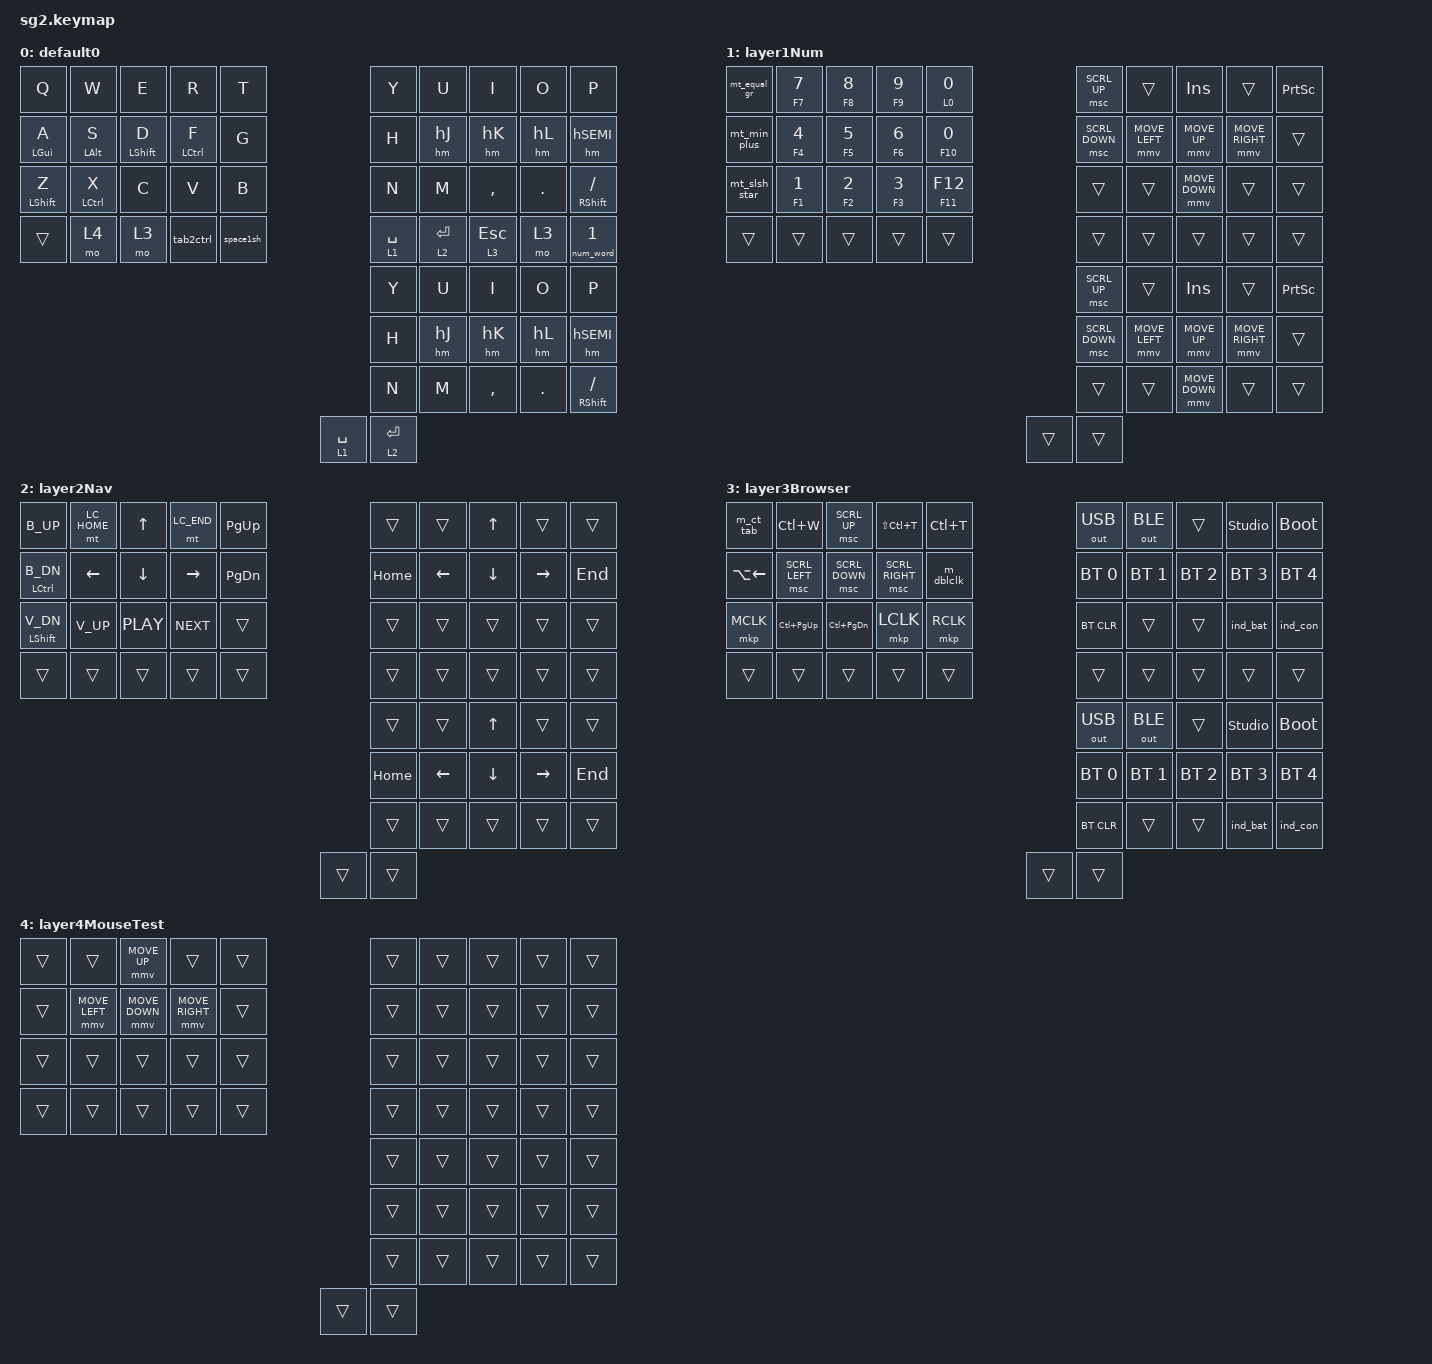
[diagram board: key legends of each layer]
#include <behaviors.dtsi>
#include <behaviors/rgbled_widget.dtsi>
#include <behaviors/num_word.dtsi>
#include <dt-bindings/zmk/keys.h>
#include <dt-bindings/zmk/bt.h>
#include <dt-bindings/zmk/outputs.h>

#define ZMK_POINTING_DEFAULT_SCRL_VAL 50
#include <dt-bindings/zmk/pointing.h>

#define hA    LGUI   A
#define hS    LALT   S
#define hD    LSHIFT D
#define hF    LCTRL  F
#define hJ    RCTRL  J
#define hK    RSHIFT K
#define hL    RALT   L
#define hSEMI RGUI   SEMI


&num_word {
  continue-list = <BSPC DEL DOT COMMA PLUS MINUS STAR FSLH EQUAL SPACE>;
  ignore-modifiers;
};

&msc {
  x-input-code = <INPUT_REL_HWHEEL>;
  y-input-code = <INPUT_REL_WHEEL>;
  time-to-max-speed-ms = <500>;
  acceleration-exponent = <1>;
};

//   888b     d888
//   8888b   d8888
//   88888b.d88888
//   888Y88888P888  8888b.   .d8888b 888d888 .d88b.  .d8888b
//   888 Y888P 888     "88b d88P"    888P"  d88""88b 88K
//   888  Y8P  888 .d888888 888      888    888  888 "Y8888b.
//   888   "   888 888  888 Y88b.    888    Y88..88P      X88
//   888       888 "Y888888  "Y8888P 888     "Y88P"   88888P'
/ {
    macros {
        ZMK_MACRO(task_manager, wait-ms = <30>; tap-ms = <40>; bindings
            = <&macro_press   &kp LCTRL &kp LSHIFT>
            , <&macro_tap     &kp ESC>
            , <&macro_release &kp LSHIFT &kp LCTRL>
            ;
        )

        ZMK_MACRO(m_al_tab, wait-ms = <30>; tap-ms = <40>; bindings
            = <&macro_press   &kp LALT>
            , <&macro_tap     &kp TAB>
            , <&macro_pause_for_release>
            , <&macro_release &kp LALT>
            ;
        )

        ZMK_MACRO(m_ct_tab, wait-ms = <30>; tap-ms = <40>; bindings
            = <&macro_press   &kp LCTRL>
            , <&macro_tap     &kp TAB>
            , <&macro_pause_for_release>
            , <&macro_release &kp LCTRL>
            ;
        )

        #define short_m wait-ms = <20>; tap-ms = <20>; bindings =

        ZMK_MACRO(m_copy_all,   short_m <&macro_tap &kp LC(HOME) &kp LC(LS(END)) &kp LC(INS) &kp LC(C)                        > ; )
        ZMK_MACRO(m_paste_all,  short_m <&macro_tap &kp LC(HOME) &kp LC(LS(END)) &kp LS(INS)                                  > ; )
        ZMK_MACRO(m_cut_all,    short_m <&macro_tap &kp LC(HOME) &kp LC(LS(END)) &kp LS(DEL)                                  > ; )
        ZMK_MACRO(m_copy,       short_m <&macro_tap &kp LC(INS) &kp LC(C)                                                     > ; )
        ZMK_MACRO(m_paste,      short_m <&macro_tap &kp LS(INS)                                                               > ; )
        ZMK_MACRO(m_cut,        short_m <&macro_tap &kp LS(DEL)                                                               > ; )
        ZMK_MACRO(m_backsp,     short_m <&macro_tap &kp BSPC                                                                  > ; )
        ZMK_MACRO(m_del_line,   short_m <&macro_tap &kp HOME &kp HOME &kp LS(END) &kp LS(RIGHT) &kp DEL                       > ; )
        ZMK_MACRO(m_undo,       short_m <&macro_tap &kp LC(Z)                                                                 > ; )
        ZMK_MACRO(m_redo,       short_m <&macro_tap &kp LC(LS(Z))                                                             > ; )
        ZMK_MACRO(m_go_back,    short_m <&macro_tap &kp LA(LEFT)                                                              > ; )
        ZMK_MACRO(m_close_tab,  short_m <&macro_tap &kp LC(W)                                                                 > ; )
        ZMK_MACRO(m_new_tab,    short_m <&macro_tap &kp LC(T)                                                                 > ; )
        ZMK_MACRO(m_reopen_tab, short_m <&macro_tap &kp LC(LS(T))                                                             > ; )
        ZMK_MACRO(m_clip_man,   short_m <&macro_tap &kp LG(V)                                                                 > ; )
        ZMK_MACRO(m_clip_prev,  short_m <&macro_tap &kp LG(V)>, <&macro_wait_time 200>, <&macro_tap &kp DOWN &kp DOWN &kp RET > ; )
        ZMK_MACRO(m_search,     short_m <&macro_tap &kp LC(C) &kp LC(F) &kp LC(V)                                             > ; )
        ZMK_MACRO(macro1,       short_m <&macro_tap &kp STAR &kp LS(U) &kp LPAR &kp LS(I) &kp RPAR &kp LS(O) &kp UNDER &kp RET> ; )
        ZMK_MACRO(m_dblclk,     short_m <&macro_tap &mkp LCLK &mkp LCLK                                                       > ; )
        ZMK_MACRO(m_bs,         short_m <&macro_tap &kp CAPS                                                                  > ; )
        ZMK_MACRO(m_bs_caps,    short_m <&macro_tap &kp CAPS &kp LC(BSPC)                                                     > ; )

        ZMK_MACRO(m_dot,          short_m <&macro_press &kp LALT>, <&macro_tap &kp KP_N4 &kp KP_N6>, <&macro_release &kp LALT>; ) // Alt + 46 = .
        ZMK_MACRO(m_com,          short_m <&macro_press &kp LALT>, <&macro_tap &kp KP_N4 &kp KP_N4>, <&macro_release &kp LALT>; ) // Alt + 44 = ,
        ZMK_MACRO(m_slash,        short_m <&macro_press &kp LALT>, <&macro_tap &kp KP_N4 &kp KP_N7>, <&macro_release &kp LALT>; ) // Alt + 47 = /
        ZMK_MACRO(m_backslash,    short_m <&macro_press &kp LALT>, <&macro_tap &kp KP_N9 &kp KP_N2>, <&macro_release &kp LALT>; ) // Alt + 92 = backslash
        ZMK_MACRO(m_colon,        short_m <&macro_press &kp LALT>, <&macro_tap &kp KP_N5 &kp KP_N8>, <&macro_release &kp LALT>; ) // Alt + 58 = colon
        ZMK_MACRO(m_semicolon,    short_m <&macro_press &kp LALT>, <&macro_tap &kp KP_N5 &kp KP_N9>, <&macro_release &kp LALT>; ) // Alt + 59 = semicolon
        ZMK_MACRO(m_semicolon_end,short_m <&macro_tap &kp END &m_semicolon>; )
        ZMK_MACRO(m_lpar,         short_m <&macro_press &kp LALT>, <&macro_tap &kp KP_N4 &kp KP_N0>, <&macro_release &kp LALT>; ) // Alt + 40 = (
        ZMK_MACRO(m_lbkt,         short_m <&macro_press &kp LALT>, <&macro_tap &kp KP_N9 &kp KP_N1>, <&macro_release &kp LALT>; ) // Alt + 91 = [
        ZMK_MACRO(m_lbrc,         short_m <&macro_press &kp LALT>, <&macro_tap &kp KP_N1 &kp KP_N2 &kp KP_N3>, <&macro_release &kp LALT>; ) // Alt + 123 = {
        ZMK_MACRO(m_lt,           short_m <&macro_press &kp LALT>, <&macro_tap &kp KP_N6 &kp KP_N0>, <&macro_release &kp LALT>; ) // Alt + 60 = <
        ZMK_MACRO(m_quote,        short_m <&macro_press &kp LALT>, <&macro_tap &kp KP_N3 &kp KP_N4>, <&macro_release &kp LALT>; ) // Alt + 34 = "
        ZMK_MACRO(m_apos,         short_m <&macro_press &kp LALT>, <&macro_tap &kp KP_N3 &kp KP_N9>, <&macro_release &kp LALT>; ) // Alt + 39 = '

        layer_mod: layer_mod {
            compatible = "zmk,behavior-macro-two-param";
            wait-ms = <0>;
            tap-ms = <0>;
            #binding-cells = <2>;
            bindings
                = <&macro_param_1to1>
                , <&macro_press &mo MACRO_PLACEHOLDER>
                , <&macro_param_2to1>
                , <&macro_press &kp MACRO_PLACEHOLDER>
                , <&macro_pause_for_release>
                , <&macro_param_2to1>
                , <&macro_release &kp MACRO_PLACEHOLDER>
                , <&macro_param_1to1>
                , <&macro_release &mo MACRO_PLACEHOLDER>
                ;
        };

        m_cs_layer2: layer_mod_ctrl_shift_layer2 {
            compatible = "zmk,behavior-macro";
            wait-ms = <30>;
            tap-ms = <30>;
            #binding-cells = <0>;
            bindings
                = <&macro_press &mo 2 &kp LCTRL &kp LSHFT>
                , <&macro_pause_for_release>
                , <&macro_release &mo 2 &kp LCTRL &kp LSHFT>
                ;
        };
    };


    //   888888b.            888                        d8b
    //   888  "88b           888                        Y8P
    //   888  .88P           888
    //   8888888K.   .d88b.  88888b.   8888b.  888  888 888  .d88b.  888d888 .d8888b
    //   888  "Y88b d8P  Y8b 888 "88b     "88b 888  888 888 d88""88b 888P"   88K
    //   888    888 88888888 888  888 .d888888 Y88  88P 888 888  888 888     "Y8888b.
    //   888   d88P Y8b.     888  888 888  888  Y8bd8P  888 Y88..88P 888          X88
    //   8888888P"   "Y8888  888  888 "Y888888   Y88P   888  "Y88P"  888      88888P'


    behaviors {

        ht: left_positional_hold_tap {  // allows shift with mouse
            compatible = "zmk,behavior-hold-tap";
            #binding-cells = <2>;
            flavor = "tap-unless-interrupted";
            tapping-term-ms = <400>;
            quick-tap-ms = <200>;
            bindings = <&kp>, <&kp>;
        };

        hm: homerow_mods {  // allows repeating z
            compatible = "zmk,behavior-hold-tap";
            #binding-cells = <2>;
            tapping-term-ms = <200>;
            quick-tap-ms = <0>;
            flavor = "tap-preferred";
            bindings = <&kp>, <&kp>;
            // retro-tap;
        };

        #define short_ht compatible = "zmk,behavior-hold-tap"; #binding-cells = <2>; flavor = "tap-preferred"; tapping-term-ms = <200>; quick-tap-ms = <0>;

        //                                                           hold            tap
        ht_dot:           hold_tap_dot           { short_ht bindings = <&m_com>,       <&m_dot>; };
        ht_paren_bracket: hold_tap_paren_bracket { short_ht bindings = <&m_lbkt>,      <&m_lpar>; };
        ht_brace_angle:   hold_tap_brace_angle   { short_ht bindings = <&m_lt>,        <&m_lbrc>; };
        ht_semi_colon:    hold_tap_semi_colon    { short_ht bindings = <&m_colon>,     <&m_semicolon>; };
        ht_quote_apos:    hold_tap_quote_apos    { short_ht bindings = <&m_apos>,      <&m_quote>; };
        // ht_under_minus:   hold_tap_under_minus   { short_ht bindings = <&kp MINUS>, <&kp UNDER>; };
        ht_slash:         hold_tap_slash         { short_ht bindings = <&m_backslash>, <&m_slash>; };
        ht_copy_all:      hold_tap_copy_all      { short_ht bindings = <&m_copy_all>,  <&m_copy>; };
        ht_paste_all:     hold_tap_paste_all     { short_ht bindings = <&m_paste_all>, <&m_paste>; };
        ht_cut_all:       hold_tap_cut_all       { short_ht bindings = <&m_cut_all>,   <&m_cut>; };
        ht_backsp_line:   hold_tap_backsp_line   { short_ht bindings = <&m_del_line>,  <&m_backsp>; };
        ht_clip_man:      hold_tap_clip_man_prev { short_ht bindings = <&m_clip_prev>, <&m_clip_man>; };
        ht_undo_redo:     hold_tap_undo_redo     { short_ht bindings = <&m_redo>,      <&m_undo>; };
        ht_back_clos:     hold_tap_go_back_close { short_ht bindings = <&m_close_tab>, <&m_go_back>; };
        ht_new_reop:      hold_tap_new_reop      { short_ht bindings = <&m_reopen_tab>,<&m_new_tab>; };
        ht_bs_caps:       hold_tap_bs_caps       { short_ht bindings = <&m_bs_caps>,   <&m_bs>; };

        #define mt_under_minus      mt MINUS         UNDER

        space1sh: space_layer1_shift {
            compatible = "zmk,behavior-mod-morph"; #binding-cells = <0>;
            bindings = <&lt 1 SPACE>, <&layer_mod 1 LSHIFT>;
            mods = <(MOD_LSFT)>; keep-mods = <(MOD_LSFT)>;
        };

        tab2ctrl: tab_layer2_ctrl {
            compatible = "zmk,behavior-mod-morph"; #binding-cells = <0>;
            bindings = <&lt 2 TAB>, <&layer_mod 2 LCTRL>;
            mods = <(MOD_LCTL)>; keep-mods = <(MOD_LCTL)>;
        };

        nav_word: nav_word {
            compatible = "zmk,behavior-auto-layer";
            #binding-cells = <1>;
            continue-list = <LEFT DOWN UP RIGHT PG_DN PG_UP HOME END>;
            ignore-modifiers;
        };
    };


    //     .d8888b.                         888
    //    d88P  Y88b                        888
    //    888    888                        888
    //    888         .d88b.  88888b.d88b.  88888b.   .d88b.  .d8888b
    //    888        d88""88b 888 "888 "88b 888 "88b d88""88b 88K
    //    888    888 888  888 888  888  888 888  888 888  888 "Y8888b.
    //    Y88b  d88P Y88..88P 888  888  888 888 d88P Y88..88P      X88
    //     "Y8888P"   "Y88P"  888  888  888 88888P"   "Y88P"   88888P'


    combos {
        compatible = "zmk,combos";
        combo_del      { key-positions = <11 12 13>; bindings = <&kp DEL      >; layers = <0 1>; };  // SDF
        combo_del2     { key-positions = <01 02   >; bindings = <&kp DEL      >; layers = <0 1>; };  // WE
        combo_esc      { key-positions = <11 13   >; bindings = <&kp ESC      >; layers = <0 1 2>; };  // SF
        combo_escR     { key-positions = <16 18   >; bindings = <&kp ESC      >; layers = <0 1 2>; };  // JL
        combo_esc_r    { key-positions = <46 48   >; bindings = <&kp ESC      >; layers = <0 1 2>; };  // JL
        combo_ret      { key-positions = <12 13   >; bindings = <&kp RET      >; layers = <0 1>; };  // DF
        combo_retR     { key-positions = <16 17   >; bindings = <&kp RET      >; layers = <0 1>; };  // JK
        combo_ret_r    { key-positions = <46 47   >; bindings = <&kp RET      >; layers = <0 1>; };  // JK
        combo_rbkt     { key-positions = < 7  8  9>; bindings = <&kp RBKT     >; layers = <0  >; };  // IOP
        combo_lbkt     { key-positions = < 8  9   >; bindings = <&kp LBKT     >; layers = <0  >; };  // OP
        combo_bslh     { key-positions = <28 29   >; bindings = <&kp BSLH     >; layers = <0  >; };  // >?
        combo_apos     { key-positions = <18 19   >; bindings = <&kp APOS     >; layers = <0  >; };  // L:
        combo_rbkt_r   { key-positions = <42 43 44>; bindings = <&kp RBKT     >; layers = <0  >; };  // IOP
        combo_lbkt_r   { key-positions = <43 44   >; bindings = <&kp LBKT     >; layers = <0  >; };  // OP
        combo_bslh_r   { key-positions = <53 54   >; bindings = <&kp BSLH     >; layers = <0  >; };  // >?
        combo_esc2_r   { key-positions = <49 54   >; bindings = <&kp ESC      >; layers = <0  >; };  // ;/
        combo_ret2_r   { key-positions = <44 49   >; bindings = <&kp RET      >; layers = <0  >; };  // p;
        combo_apos_r   { key-positions = <48 49   >; bindings = <&kp APOS     >; layers = <0  >; };  // L:
        combo_task     { key-positions = <00 01   >; bindings = <&task_manager>; layers = <0  >; };  // QW
        combo_cshf     { key-positions = <20 13   >; bindings = <&sk LS(LCTRL)>; layers = <0  >; };  // ZF
        combo_c        { key-positions = <00 13   >; bindings = <&sk LCTRL    >; layers = <0  >; };  // QF
        combo_macro1   { key-positions = < 7 16   >; bindings = <&macro1      >; layers = <0  >; };  // IJ
        combo_macro1_r { key-positions = <42 46   >; bindings = <&macro1      >; layers = <0  >; };  // IJ
        combo_shift1   { key-positions = <12 34   >; bindings = <&layer_mod 1 LSHIFT>; layers = <0>; slow-release;};  // Dspace
        combo_ctrl1    { key-positions = <13 34   >; bindings = <&layer_mod 1 LCTRL >; layers = <0>; slow-release;};  // Fspace
        combo_capsw    { key-positions = <10 20   >; bindings = <&caps_word>;            layers = <0>; };  // AZ
        combo_capsw2   { key-positions = <12 17   >; bindings = <&caps_word>;            layers = <0>; };  // DK
        combo_capsw2_r { key-positions = <12 47   >; bindings = <&caps_word>;            layers = <0>; };  // DK
        combo_brack1   { key-positions = <03 04   >; bindings = <&ht_paren_bracket 0 0>; layers = <0>; };  // RT
    //  00q 01w 02e 03r 04t         05y 06u 07i 08o 09p
    //  10a 11s 12d 13f 14g         15h 16j 17k 18l 19;
    //  20z 21x 22c 23v 24b         25n 26m 27, 28. 29/
    //      30  31  32  33t 34s 35s 36r 37e 38 39
    //                              40y 41u 42i 43o 44p
    //                              45h 46j 47k 48l 49;
    //                              50n 51m 52, 53. 54/
    //                          55s 56r
        combo_brack2   { key-positions = <13 14   >; bindings = <&ht_brace_angle   0 0>; layers = <0>; };  // FG
        combo_caps_bs  { key-positions = <10 13   >; bindings = <&ht_bs_caps       0 0>; layers = <0>; };  // AF
        combo_colon    { key-positions = <03 13   >; bindings = <&ht_semi_colon    0 0>; layers = <0>; };  // RF
        combo_quote    { key-positions = <02 12   >; bindings = <&ht_quote_apos    0 0>; layers = <0>; };  // ED
        combo_under    { key-positions = <13 23   >; bindings = <&mt_under_minus      >; layers = <0>; };  // FV
        combo_slash    { key-positions = <23 24   >; bindings = <&ht_slash         0 0>; layers = <0>; };  // VB
        combo_search   { key-positions = <22 13   >; bindings = <&m_search>;             layers = <0>; };  // CF
        combo_num_wo   { key-positions = <14 34   >; bindings = <&num_word 1>;           layers = <0>; };  // Gspace
        combo_nav_wo   { key-positions = <14 33   >; bindings = <&nav_word 2>;           layers = <0>; };  // Gtab
        combo_colonE   { key-positions = <04 14   >; bindings = <&m_semicolon_end>;      layers = <0>; };  // TG
        combo_repeat   { key-positions = <02 03   >; bindings = <&key_repeat >;          layers = <0>; };  // ER
        combo_al_tab   { key-positions = <11 33   >; bindings = <&m_al_tab >;            layers = <0>; slow-release; };  // Stab
        combo_ct_tab   { key-positions = <13 33   >; bindings = <&m_ct_tab >;            layers = <0>; slow-release; };  // Ftab
        combo_copy_all { key-positions = <21 22   >; bindings = <&ht_copy_all 0 0>;      layers = <0>; };  // XC
        combo_paste_all{ key-positions = <22 23   >; bindings = <&ht_paste_all 0 0>;     layers = <0>; };  // CV
        combo_cut_all  { key-positions = <20 21   >; bindings = <&ht_cut_all 0 0>;       layers = <0>; };  // ZX
        combo_bsp_line { key-positions = <11 12   >; bindings = <&ht_backsp_line 0 0>;   layers = <0 1>; };// SD
        combo_bsp_lineR{ key-positions = <17 18   >; bindings = <&ht_backsp_line 0 0>;   layers = <0 1>; };// KL
        combo_bsp_lin_r{ key-positions = <47 48   >; bindings = <&ht_backsp_line 0 0>;   layers = <0 1>; };// KL
        combo_clip_man { key-positions = <21 22 23>; bindings = <&ht_clip_man 0 0>;      layers = <0>; };  // XCV
        combo_undo     { key-positions = <10 11   >; bindings = <&ht_undo_redo 0 0>;     layers = <0>; };  // AS
        combo_back_clos{ key-positions = <11 12   >; bindings = <&ht_back_clos 0 0>;     layers = <2>; };  // SD
        combo_new_reop { key-positions = <12 13   >; bindings = <&ht_new_reop 0 0>;      layers = <2>; };  // DF
        combo_sym_1k    { key-positions = <17 21   >; bindings = <&kp LS(N1)>;             layers = <0>; };
        combo_sym_2k    { key-positions = <17 22   >; bindings = <&kp LS(N2)>;             layers = <0>; };
        combo_sym_3k    { key-positions = <17 23   >; bindings = <&kp LS(N3)>;             layers = <0>; };
        combo_sym_4k    { key-positions = <17 11   >; bindings = <&kp LS(N4)>;             layers = <0>; };
        combo_sym_5k    { key-positions = <17 12   >; bindings = <&kp LS(N5)>;             layers = <0>; };
        combo_sym_6k    { key-positions = <17 13   >; bindings = <&kp LS(N6)>;             layers = <0>; };
        combo_sym_7k    { key-positions = <17 01   >; bindings = <&kp LS(N7)>;             layers = <0>; };
        combo_sym_8k    { key-positions = <17 02   >; bindings = <&kp LS(N8)>;             layers = <0>; };
        combo_sym_9k    { key-positions = <17 03   >; bindings = <&kp LS(N9)>;             layers = <0>; };
        combo_sym_0k    { key-positions = <17 14   >; bindings = <&kp LS(N0)>;             layers = <0>; };
        combo_sym_1k_r  { key-positions = <47 21   >; bindings = <&kp LS(N1)>;             layers = <0>; };
        combo_sym_2k_r  { key-positions = <47 22   >; bindings = <&kp LS(N2)>;             layers = <0>; };
        combo_sym_3k_r  { key-positions = <47 23   >; bindings = <&kp LS(N3)>;             layers = <0>; };
        combo_sym_4k_r  { key-positions = <47 11   >; bindings = <&kp LS(N4)>;             layers = <0>; };
        combo_sym_5k_r  { key-positions = <47 12   >; bindings = <&kp LS(N5)>;             layers = <0>; };
        combo_sym_6k_r  { key-positions = <47 13   >; bindings = <&kp LS(N6)>;             layers = <0>; };
        combo_sym_7k_r  { key-positions = <47 01   >; bindings = <&kp LS(N7)>;             layers = <0>; };
        combo_sym_8k_r  { key-positions = <47 02   >; bindings = <&kp LS(N8)>;             layers = <0>; };
        combo_sym_9k_r  { key-positions = <47 03   >; bindings = <&kp LS(N9)>;             layers = <0>; };
        combo_sym_0k_r  { key-positions = <47 14   >; bindings = <&kp LS(N0)>;             layers = <0>; };
        combo_sym_1s    { key-positions = <34 21   >; bindings = <&kp LS(N1)>;             layers = <0>; };
        combo_sym_2s    { key-positions = <34 22   >; bindings = <&kp LS(N2)>;             layers = <0>; };
        combo_sym_3s    { key-positions = <34 23   >; bindings = <&kp LS(N3)>;             layers = <0>; };
        combo_sym_4s    { key-positions = <34 11   >; bindings = <&kp LS(N4)>;             layers = <0>; };
        combo_sym_5s    { key-positions = <34 12   >; bindings = <&kp LS(N5)>;             layers = <0>; };
        combo_sym_6s    { key-positions = <34 13   >; bindings = <&kp LS(N6)>;             layers = <0>; };
        combo_sym_7s    { key-positions = <34 01   >; bindings = <&kp LS(N7)>;             layers = <0>; };
        combo_sym_8s    { key-positions = <34 02   >; bindings = <&kp LS(N8)>;             layers = <0>; };
        combo_sym_9s    { key-positions = <34 03   >; bindings = <&kp LS(N9)>;             layers = <0>; };
        combo_sym_0s    { key-positions = <34 14   >; bindings = <&kp LS(N0)>;             layers = <0>; };

        combo_lclk      { key-positions = <12 13   >; bindings = <&mkp LCLK >;             layers = <3>; };  // DF
        combo_rclk      { key-positions = <11 12   >; bindings = <&mkp RCLK >;             layers = <3>; };  // SD
        combo_mclk      { key-positions = <11 13   >; bindings = <&mkp MCLK >;             layers = <3>; };  // SF
        combo_4clk      { key-positions = <11 12 13>; bindings = <&mkp MB4  >;             layers = <3>; };  // SDF

        combo_bt0       { key-positions = <15 25   >; bindings = <&bt BT_SEL 0>;           layers = <0>; };  // HN
        combo_bt1       { key-positions = <16 26   >; bindings = <&bt BT_SEL 1>;           layers = <0>; };  // JM
        combo_bt2       { key-positions = <17 27   >; bindings = <&bt BT_SEL 2>;           layers = <0>; };  // K<
        combo_out_tog   { key-positions = <05 06   >; bindings = <&out OUT_TOG>;           layers = <0>; };  // YU
        combo_bt0_r     { key-positions = <45 50   >; bindings = <&bt BT_SEL 0>;           layers = <0>; };  // HN
        combo_bt1_r     { key-positions = <46 51   >; bindings = <&bt BT_SEL 1>;           layers = <0>; };  // JM
        combo_bt2_r     { key-positions = <47 52   >; bindings = <&bt BT_SEL 2>;           layers = <0>; };  // K<
        combo_out_tog_r { key-positions = <40 41   >; bindings = <&out OUT_TOG>;           layers = <0>; };  // YU
    };

    //  00q 01w 02e 03r 04t         05y 06u 07i 08o 09p
    //  10a 11s 12d 13f 14g         15h 16j 17k 18l 19;
    //  20z 21x 22c 23v 24b         25n 26m 27, 28. 29/
    //      30  31  32  33t 34s 35s 36r 37e 38 39
    //                              40y 41u 42i 43o 44p
    //                              45h 46j 47k 48l 49;
    //                              50n 51m 52, 53. 54/
    //                          55s 56r


    //   888    d8P
    //   888   d8P
    //   888  d8P
    //   888d88K      .d88b.  888  888 88888b.d88b.   8888b.  88888b.
    //   8888888b    d8P  Y8b 888  888 888 "888 "88b     "88b 888 "88b
    //   888  Y88b   88888888 888  888 888  888  888 .d888888 888  888
    //   888   Y88b  Y8b.     Y88b 888 888  888  888 888  888 888 d88P
    //   888    Y88b  "Y8888   "Y88888 888  888  888 "Y888888 88888P"
    //                             888                        888
    //                        Y8b d88P                        888
    //                         "Y88P"                         888


    keymap {
        compatible = "zmk,keymap";

        default0 { bindings = <
//╭── 00      ──┬── 01     ──┬── 02     ──┬── 03     ──┬── 04     ──╮                        ╭── 05      ──┬── 06    ──┬── 07    ──┬── 08   ──┬── 09       ──╮
  &kp Q         &kp W        &kp E        &kp R        &kp T                                 &kp Y         &kp U       &kp I       &kp O      &kp P
//├── 10      ──┼── 11     ──┼── 12     ──┼── 13     ──┼── 14     ──┤                        ├── 15      ──┼── 16    ──┼── 17    ──┼── 18   ──┼── 19       ──┤
  &hm LGUI A    &hm LALT S   &hm LSHFT D  &hm LCTRL F  &kp G                                 &kp H         &hm hJ      &hm hK      &hm hL     &hm hSEMI
//├── 20      ──┼── 21     ──┼── 22     ──┼── 23     ──┼── 24     ──┤                        ├── 25      ──┼── 26    ──┼── 27    ──┼── 28   ──┼── 29       ──┤
  &hm LSHFT Z   &hm LCTRL X  &kp C        &kp V        &kp B                                 &kp N         &kp M       &kp COMMA   &kp DOT    &hm RSHFT FSLH
//╰──         ──┼── 30     ──┴── 31     ──┼── 32     ──┼── 33     ──┼── 34    ──╮╭── 35    ──┼── 36      ──┼── 37    ──┼── 38    ──┼── 39   ──┴──          ──╯
                &trans       &mo 4        &mo 3        &tab2ctrl    &space1sh    &lt 1 SPACE &lt 2 RET     &lt 3 ESC   &mo 3       &num_word 1
//              ╰──        ──┴──        ──┴──        ──┴──        ──┴──       ──╯╰──       ──┴──         ──┴──       ──┴──       ──┴──      ──╯
//                                                                                           ╭── 40      ──┬── 41    ──┬── 42    ──┬── 43   ──┬── 44       ──╮
                                                                                             &kp Y         &kp U       &kp I       &kp O      &kp P
//                                                                                           ├── 45      ──┼── 46    ──┼── 47    ──┼── 48   ──┼── 49       ──┤
                                                                                             &kp H         &hm hJ      &hm hK      &hm hL     &hm hSEMI
//                                                                                           ├── 50      ──┼── 51    ──┼── 52    ──┼── 53   ──┼── 54       ──┤
                                                                                             &kp N         &kp M       &kp COMMA   &kp DOT    &hm RSHFT FSLH
//                                                                               ╭── 55    ──┼── 56      ──┼──       ──┴──       ──┴──      ──┴──          ──╯
                                                                                 &lt 1 SPACE &lt 2 RET     >; };
//                                                                               ╰──       ──┴──         ──╯

//                          hold         tap
#define mt_min_plus      mt PLUS         MINUS
#define mt_equal_gr      mt GRAVE        EQUAL
#define mt_slsh_star     mt STAR         KP_SLASH
        layer1Num { bindings = <
//╭─00─       ──┬─01─      ──┬─02─      ──┬─03─      ──┬─04─      ──╮                         ╭─05─      ──┬─06─     ──┬─07─     ──┬─08─    ──┬─09─      ──╮
  &mt_equal_gr  &mt F7 N7    &mt F8 N8    &mt F9 N9    &ht_dot 0 0                            &msc SCRL_UP &trans      &kp INSERT  &trans     &kp PSCRN
//├─10─       ──┼─11─      ──┼─12─      ──┼─13─      ──┼─14─      ──┤                         ├─15─      ──┼─16─     ──┼─17─     ──┼─18─    ──┼─19─      ──┤
  &mt_min_plus  &mt F4 N4    &mt F5 N5    &mt F6 N6    &mt F10 N0                             &msc SCRL_DOWN &mmv MOVE_LEFT &mmv MOVE_UP &mmv MOVE_RIGHT &trans
//├─20─       ──┼─21─      ──┼─22─      ──┼─23─      ──┼─24─      ──┤                         ├─25─      ──┼─26─     ──┼─27─     ──┼─28─    ──┼─29─      ──┤
  &mt_slsh_star &mt F1 N1    &mt F2 N2    &mt F3 N3    &mt F11 F12                            &trans       &trans      &mmv MOVE_DOWN &trans  &trans
//╰──         ──┼── 30     ──┴── 31     ──┼── 32     ──┼── 33     ──┼── 34    ──╮╭── 35     ──┼── 36     ──┼── 37    ──┼── 38    ──┼── 39   ──┴──        ──╯
                &trans       &trans       &trans       &trans       &trans       &trans       &trans       &trans      &trans      &trans
//              ╰──        ──┴──        ──┴──        ──┴──        ──┴──       ──╯╰──        ──┴──        ──┴──       ──┴──       ──┴──      ──╯
//                                                                                            ╭─ 40      ──┬── 41    ──┬── 42    ──┬── 43   ──┬── 44      ──╮
                                                                                              &msc SCRL_UP &trans      &kp INSERT  &trans     &kp PSCRN
//                                                                                            ├─ 45      ──┼── 46    ──┼── 47    ──┼── 48   ──┼── 49      ──┤
                                                                                              &msc SCRL_DOWN &mmv MOVE_LEFT &mmv MOVE_UP &mmv MOVE_RIGHT &trans
//                                                                                            ├─ 50      ──┼── 51    ──┼── 52    ──┼── 53   ──┼── 54      ──┤
                                                                                              &trans       &trans      &mmv MOVE_DOWN &trans  &trans
//                                                                               ╭── 55     ──┼─ 56      ──┼──       ──┴──       ──┴──      ──┴──         ──╯
                                                                                 &trans       &trans       >; };
//                                                                               ╰──        ──┴──        ──╯
#define B_UP    C_BRI_UP
#define B_DN    C_BRI_DN
#define V_DN    C_VOL_DN
#define V_UP    C_VOL_UP
#define PLAY    C_PLAY_PAUSE
#define LC_HOME LC(HOME) HOME
#define LC_END  LC(END) END
#define SCRL_U  &msc SCRL_UP
#define SCRL_D  &msc SCRL_DOWN
#define SCRL_L  &msc SCRL_LEFT
#define SCRL_R  &msc SCRL_RIGHT
#define mmv_U   &mmv MOVE_UP
#define mmv_D   &mmv MOVE_DOWN
#define mmv_L   &mmv MOVE_LEFT
#define mmv_R   &mmv MOVE_RIGHT
        layer2Nav { bindings = <
//╭─00─       ──┬─01─      ──┬─02─      ──┬─03─      ──┬─04─      ──╮                         ╭─05─      ──┬─06─     ──┬─07─     ──┬─08─    ──┬─09─      ──╮
  &kp B_UP      &mt LC_HOME  &kp UP       &mt LC_END   &kp PG_UP                              &trans       &trans      &kp UP      &trans     &trans
//├─10─       ──┼─11─      ──┼─12─      ──┼─13─      ──┼─14─      ──┤                         ├─15─      ──┼─16─     ──┼─17─     ──┼─18─    ──┼─19─      ──┤
  &hm LCTRL B_DN &kp LEFT    &kp DOWN     &kp RIGHT    &kp PG_DN                              &kp HOME     &kp LEFT    &kp DOWN    &kp RIGHT  &kp END
//├─20─       ──┼─21─      ──┼─22─      ──┼─23─      ──┼─24─      ──┤                         ├─25─      ──┼─26─     ──┼─27─     ──┼─28─    ──┼─29─      ──┤
  &hm LSHFT V_DN &kp V_UP    &kp PLAY     &kp C_NEXT   &trans                                 &trans       &trans      &trans      &trans     &trans
//╰──         ──┼── 30     ──┴── 31     ──┼── 32     ──┼── 33     ──┼── 34    ──╮╭── 35     ──┼── 36     ──┼── 37    ──┼── 38    ──┼── 39   ──┴──        ──╯
                &trans       &trans       &trans       &trans       &trans       &trans       &trans       &trans      &trans      &trans
//              ╰──        ──┴──        ──┴──        ──┴──        ──┴──       ──╯╰──        ──┴──        ──┴──       ──┴──       ──┴──      ──╯
//                                                                                            ╭─ 40      ──┬── 41    ──┬── 42    ──┬── 43   ──┬── 44      ──╮
                                                                                              &trans       &trans      &kp UP      &trans     &trans
//                                                                                            ├─ 45      ──┼── 46    ──┼── 47    ──┼── 48   ──┼── 49      ──┤
                                                                                              &kp HOME     &kp LEFT    &kp DOWN    &kp RIGHT  &kp END
//                                                                                            ├─ 50      ──┼── 51    ──┼── 52    ──┼── 53   ──┼── 54      ──┤
                                                                                              &trans       &trans      &trans      &trans     &trans
//                                                                               ╭── 55     ──┼─ 56      ──┼──       ──┴──       ──┴──      ──┴──         ──╯
                                                                                 &trans       &trans       >; };
//                                                                               ╰──        ──┴──        ──╯
        layer3Browser { bindings = <
//╭─00─       ──┬─01─      ──┬─02─      ──┬─03─      ──┬─04─      ──╮                         ╭─05─      ──┬─06─     ──┬─07─     ──┬─08─    ──┬─09─      ──╮
  &m_ct_tab     &kp LC(W)    SCRL_U       &kp LS(LC(T)) &kp LC(T)                              &out OUT_USB &out OUT_BLE &trans &studio_unlock &bootloader
//├─10─       ──┼─11─      ──┼─12─      ──┼─13       ──┼─14─      ──┤                         ├─15─      ──┼─16─     ──┼─17─     ──┼─18─    ──┼─19─      ──┤
  &kp LA(LEFT)  SCRL_L       SCRL_D       SCRL_R       &m_dblclk                              &bt BT_SEL 0 &bt BT_SEL 1 &bt BT_SEL 2 &bt BT_SEL 3 &bt BT_SEL 4
//├─20─       ──┼─21─      ──┼─22─      ──┼─23       ──┼─24─      ──┤                         ├─25─      ──┼─26─     ──┼─27─     ──┼─28─    ──┼─29─      ──┤
  &mkp MCLK    &kp LC(PG_UP) &kp LC(PG_DN) &mkp LCLK   &mkp RCLK                              &bt BT_CLR   &trans      &trans      &ind_bat   &ind_con
//╰──         ──┼── 30     ──┴── 31     ──┼── 32     ──┼── 33     ──┼── 34    ──╮╭── 35     ──┼── 36     ──┼── 37    ──┼── 38    ──┼── 39   ──┴──        ──╯
                &trans       &trans       &trans       &trans       &trans       &trans       &trans       &trans      &trans      &trans
//              ╰──        ──┴──        ──┴──        ──┴──        ──┴──       ──╯╰──        ──┴──        ──┴──       ──┴──       ──┴──      ──╯
//                                                                                            ╭─ 40      ──┬── 41    ──┬── 42    ──┬── 43   ──┬── 44─      ──╮
                                                                                              &out OUT_USB &out OUT_BLE &trans &studio_unlock &bootloader
//                                                                                            ├─ 45      ──┼── 46    ──┼── 47    ──┼── 48   ──┼── 49─      ──┤
                                                                                              &bt BT_SEL 0 &bt BT_SEL 1 &bt BT_SEL 2 &bt BT_SEL 3 &bt BT_SEL 4
//                                                                                            ├─ 50      ──┼── 51    ──┼── 52    ──┼── 53   ──┼── 54       ──┤
                                                                                              &bt BT_CLR   &trans      &trans      &ind_bat   &ind_con
//                                                                               ╭── 55     ──┼── 56     ──┼──       ──┴──       ──┴──      ──┴──          ──╯
                                                                                 &trans       &trans       >; };
//                                                                               ╰──        ──┴──        ──╯

        layer4MouseTest { bindings = <
//╭─00─       ──┬─01─      ──┬─02─      ──┬─03─      ──┬─04─       ──╮                        ╭─05─      ──┬─06─     ──┬─07─     ──┬─08─    ──┬─09─      ──╮
  &trans        &trans       mmv_U        &trans       &trans                                 &trans       &trans      &trans      &trans     &trans
//├─10─       ──┼─11─      ──┼─12─      ──┼─13─      ──┼─14─       ──┤                        ├─15─      ──┼─16─     ──┼─17─     ──┼─18─    ──┼─19─      ──┤
  &trans        mmv_L        mmv_D        mmv_R        &trans                                 &trans       &trans      &trans      &trans     &trans
//├─20─       ──┼─21─      ──┼─22─      ──┼─23─      ──┼─24─       ──┤                        ├─25─      ──┼─26─     ──┼─27─     ──┼─28─    ──┼─29─      ──┤
  &trans        &trans       &trans       &trans       &trans                                 &trans       &trans      &trans      &trans     &trans
//╰──         ──┼── 30     ──┼── 31     ──┼── 32     ──┼── 33      ──┼── 34    ──╮╭── 35    ──┼── 36     ──┼── 37    ──┼── 38    ──┼── 39   ──┴──        ──╯
                &trans       &trans       &trans       &trans        &trans       &trans      &trans       &trans      &trans      &trans
//              ╰──        ──┴──        ──┴──        ──┴──         ──┴──       ──╯╰──       ──┴──        ──┴──       ──┴──       ──┴──      ──╯
//                                                                                            ╭─ 40      ──┬── 41    ──┬── 42    ──┬── 43   ──┬── 44      ──╮
                                                                                              &trans       &trans      &trans      &trans     &trans
//                                                                                            ├─ 45      ──┼── 46    ──┼── 47    ──┼── 48   ──┼── 49      ──┤
                                                                                              &trans       &trans      &trans      &trans     &trans
//                                                                                            ├─ 50      ──┼── 51    ──┼── 52    ──┼── 53   ──┼── 54      ──┤
                                                                                              &trans       &trans      &trans      &trans     &trans
//                                                                                ╭── 55    ──┼─ 56      ──┼──       ──┴──       ──┴──      ──┴──         ──╯
                                                                                  &trans      &trans       >; };
//                                                                                ╰──       ──┴──        ──╯
//         layerTemplate { bindings = <
// //╭─00─       ──┬─01─      ──┬─02─      ──┬─03─      ──┬─04─       ──╮                        ╭─05─      ──┬─06─     ──┬─07─     ──┬─08─    ──┬─09─      ──╮
//   &trans        &trans       &trans       &trans       &trans                                 &trans       &trans      &trans      &trans     &trans
// //├─10─       ──┼─11─      ──┼─12─      ──┼─13─      ──┼─14─       ──┤                        ├─15─      ──┼─16─     ──┼─17─     ──┼─18─    ──┼─19─      ──┤
//   &trans        &trans       &trans       &trans       &trans                                 &trans       &trans      &trans      &trans     &trans
// //├─20─       ──┼─21─      ──┼─22─      ──┼─23─      ──┼─24─       ──┤                        ├─25─      ──┼─26─     ──┼─27─     ──┼─28─    ──┼─29─      ──┤
//   &trans        &trans       &trans       &trans       &trans                                 &trans       &trans      &trans      &trans     &trans
// //╰──         ──┼── 30     ──┼── 31     ──┼── 32     ──┼── 33      ──┼── 34    ──╮╭── 35    ──┼── 36     ──┼── 37    ──┼── 38    ──┼── 39   ──┴──        ──╯
//                 &trans       &trans       &trans       &trans        &trans       &trans      &trans       &trans      &trans      &trans
// //              ╰──        ──┴──        ──┴──        ──┴──         ──┴──       ──╯╰──       ──┴──        ──┴──       ──┴──       ──┴──      ──╯
// //                                                                                            ╭─ 40      ──┬── 41    ──┬── 42    ──┬── 43   ──┬── 44      ──╮
//                                                                                               &trans       &trans      &trans      &trans     &trans
// //                                                                                            ├─ 45      ──┼── 46    ──┼── 47    ──┼── 48   ──┼── 49      ──┤
//                                                                                               &trans       &trans      &trans      &trans     &trans
// //                                                                                            ├─ 50      ──┼── 51    ──┼── 52    ──┼── 53   ──┼── 54      ──┤
//                                                                                               &trans       &trans      &trans      &trans     &trans
// //                                                                                ╭── 55    ──┼─ 56      ──┼──       ──┴──       ──┴──      ──┴──         ──╯
//                                                                                   &trans      &trans       >; };
// //                                                                                ╰──       ──┴──        ──╯

    };
};
